VERSION ""

NS_ :

BS_:

BU_:
VAL_TABLE_ MPPT_Enabled 1 "Enabled" 0 "Disabled" ;
VAL_TABLE_ MPPT_Mode 6 "Fault" 5 "Temperature De-rating" 4 "Constant Output Current" 3 "Constand Output Voltage" 2 "Minimum Input Current" 1 "Constand Input Current" 0 "Constand Input Voltage" ;
VAL_TABLE_ MPPT_Fault 8 "Fault" 7 "Phase Over Current" 6 "Input Under Current" 5 "Input Over Current" 4 "Output Over Current" 3 "Output Over Voltage" 2 "Input Over Voltage" 1 "Configuration Error" 0 "OK(No Fault)" ;

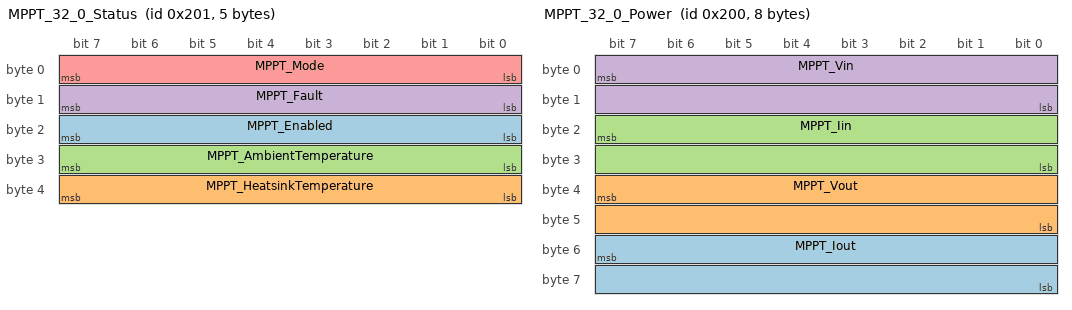
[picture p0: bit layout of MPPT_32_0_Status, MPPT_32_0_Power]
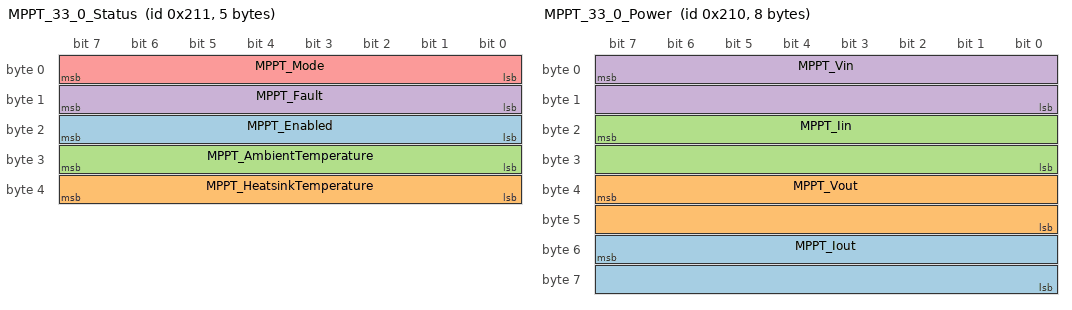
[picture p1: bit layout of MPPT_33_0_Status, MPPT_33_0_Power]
BO_ 513 MPPT_32_0_Status: 5 Vector__XXX
 SG_ MPPT_Enabled : 16|8@1- (1,0) [0|0] "" Vector__XXX
 SG_ MPPT_HeatsinkTemperature : 39|8@0- (1,0) [-128|127] "C" Vector__XXX
 SG_ MPPT_AmbientTemperature : 31|8@0- (1,0) [-128|127] "C" Vector__XXX
 SG_ MPPT_Fault : 8|8@1+ (1,0) [0|0] "" Vector__XXX
 SG_ MPPT_Mode : 0|8@1+ (1,0) [0|0] "" Vector__XXX

BO_ 512 MPPT_32_0_Power: 8 Vector__XXX
 SG_ MPPT_Iout : 55|16@0- (0.0005,0) [0|0] "A" Vector__XXX
 SG_ MPPT_Vout : 39|16@0- (0.01,0) [-327.68|327.67] "V" Vector__XXX
 SG_ MPPT_Iin : 23|16@0- (0.0005,0) [-16.384|16.3835] "A" Vector__XXX
 SG_ MPPT_Vin : 7|16@0- (0.01,0) [-327.68|327.67] "V" Vector__XXX

 BO_ 529 MPPT_33_0_Status: 5 Vector__XXX
 SG_ MPPT_Enabled : 16|8@1- (1,0) [0|0] "" Vector__XXX
 SG_ MPPT_HeatsinkTemperature : 39|8@0- (1,0) [-128|127] "C" Vector__XXX
 SG_ MPPT_AmbientTemperature : 31|8@0- (1,0) [-128|127] "C" Vector__XXX
 SG_ MPPT_Fault : 8|8@1+ (1,0) [0|0] "" Vector__XXX
 SG_ MPPT_Mode : 0|8@1+ (1,0) [0|0] "" Vector__XXX

BO_ 528 MPPT_33_0_Power: 8 Vector__XXX
 SG_ MPPT_Iout : 55|16@0- (0.0005,0) [0|0] "A" Vector__XXX
 SG_ MPPT_Vout : 39|16@0- (0.01,0) [-327.68|327.67] "V" Vector__XXX
 SG_ MPPT_Iin : 23|16@0- (0.0005,0) [-16.384|16.3835] "A" Vector__XXX
 SG_ MPPT_Vin : 7|16@0- (0.01,0) [-327.68|327.67] "V" Vector__XXX

VAL_ 513 MPPT_Enabled 1 "Enabled" 0 "Disabled" ;
VAL_ 513 MPPT_Fault 6 "Fault" 5 "Temperature De-rating" 4 "Constant Output Current" 3 "Constand Output Voltage" 2 "Minimum Input Current" 1 "Constand Input Current" 0 "Constand Input Voltage" ;
VAL_ 513 MPPT_Mode 8 "Fault" 7 "Phase Over Current" 6 "Input Under Current" 5 "Input Over Current" 4 "Output Over Current" 3 "Output Over Voltage" 2 "Input Over Voltage" 1 "Configuration Error" 0 "OK(No Fault)" ;
